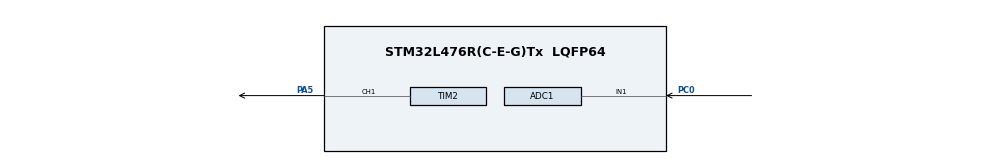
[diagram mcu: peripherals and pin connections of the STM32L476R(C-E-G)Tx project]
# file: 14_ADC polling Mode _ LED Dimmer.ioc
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ADC1.Channel-0\#ChannelRegularConversion=ADC_CHANNEL_1
ADC1.EnableAnalogWatchDog1=false
ADC1.NbrOfConversionFlag=1
ADC1.OffsetNumber-0\#ChannelRegularConversion=ADC_OFFSET_NONE
ADC1.Rank-0\#ChannelRegularConversion=1
ADC1.SamplingTime-0\#ChannelRegularConversion=ADC_SAMPLETIME_2CYCLES_5
ADC1.master=1
Mcu.Family=STM32L4
Mcu.Name=STM32L476R(C-E-G)Tx
Mcu.Package=LQFP64
NVIC.PriorityGroup=NVIC_PRIORITYGROUP_4
PA5.Signal=S_TIM2_CH1
PC0.Signal=ADCx_IN1
ProjectManager.HeapSize=0x200
ProjectManager.StackSize=0x400
ProjectManager.TargetToolchain=STM32CubeIDE
RCC.ADCFreq_Value=12000000
RCC.HSE_VALUE=8000000
RCC.HSI_VALUE=16000000
RCC.LSE_VALUE=32768
RCC.MSI_VALUE=4000000
RCC.PLLSAI1N=18
RCC.PLLSAI1R=RCC_PLLR_DIV6
RCC.USBFreq_Value=36000000
RCC.VCOOutputFreq_Value=32000000
SH.ADCx_IN1.0=ADC1_IN1,IN1-Single-Ended
SH.S_TIM2_CH1.0=TIM2_CH1,PWM Generation1 CH1
TIM2.Channel-PWM\ Generation1\ CH1=TIM_CHANNEL_1
TIM2.Period=1000
TIM2.Prescaler=3
TIM2.Pulse-PWM\ Generation1\ CH1=500
VP_TIM2_VS_ClockSourceINT.Mode=Internal
board=custom

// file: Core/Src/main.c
/* USER CODE BEGIN Header */
/**
  ******************************************************************************
  * @file           : main.c
  * @brief          : Main program body
  ******************************************************************************
  * @attention
  *
  * Copyright (c) 2023 STMicroelectronics.
  * All rights reserved.
  *
  * This software is licensed under terms that can be found in the LICENSE file
  * in the root directory of this software component.
  * If no LICENSE file comes with this software, it is provided AS-IS.
  *
  ******************************************************************************
  */
/* USER CODE END Header */
#include "main.h"

ADC_HandleTypeDef hadc1;

TIM_HandleTypeDef htim2;

void SystemClock_Config(void);
static void MX_GPIO_Init(void);
static void MX_ADC1_Init(void);
static void MX_TIM2_Init(void);

/* USER CODE BEGIN 0 */
uint16_t ADC_RES = 0;
uint32_t k = 0;

/* USER CODE END 0 */

int main(void)
{

  /* MCU Configuration--------------------------------------------------------*/

  /* Reset of all peripherals, Initializes the Flash interface and the Systick. */
  HAL_Init();

  /* Configure the system clock */
  SystemClock_Config();

  /* Initialize all configured peripherals */
  MX_GPIO_Init();
  MX_ADC1_Init();
  MX_TIM2_Init();
  /* USER CODE BEGIN 2 */
  HAL_TIM_PWM_Start(&htim2,TIM_CHANNEL_1);
  // Calibrate The ADC On Power-Up For Better Accuracy
  HAL_ADCEx_Calibration_Start(&hadc1,ADC_SINGLE_ENDED);

  /* USER CODE END 2 */

  /* Infinite loop */
  while (1)
  {

    /* USER CODE BEGIN 3 */
    // Start ADC Conversion
    HAL_ADC_Start(&hadc1);
    // Poll ADC1 Perihperal & TimeOut = 1mSec
    HAL_ADC_PollForConversion(&hadc1, 5);
    // Read The ADC Conversion Result & Map It To PWM DutyCycle
    ADC_RES = HAL_ADC_GetValue(&hadc1);
    TIM2->CCR1 = (ADC_RES<<10);
    k=(ADC_RES<<10);
    HAL_Delay(5);
  }
  /* USER CODE END 3 */
}

void SystemClock_Config(void)
{
  RCC_OscInitTypeDef RCC_OscInitStruct = {0};
  RCC_ClkInitTypeDef RCC_ClkInitStruct = {0};

  /** Configure the main internal regulator output voltage
  */
  if (HAL_PWREx_ControlVoltageScaling(PWR_REGULATOR_VOLTAGE_SCALE1) != HAL_OK)
  {
    Error_Handler();
  }

  /** Initializes the RCC Oscillators according to the specified parameters
  * in the RCC_OscInitTypeDef structure.
  */
  RCC_OscInitStruct.OscillatorType = RCC_OSCILLATORTYPE_MSI;
  RCC_OscInitStruct.MSIState = RCC_MSI_ON;
  RCC_OscInitStruct.MSICalibrationValue = 0;
  RCC_OscInitStruct.MSIClockRange = RCC_MSIRANGE_6;
  RCC_OscInitStruct.PLL.PLLState = RCC_PLL_NONE;
  if (HAL_RCC_OscConfig(&RCC_OscInitStruct) != HAL_OK)
  {
    Error_Handler();
  }

  /** Initializes the CPU, AHB and APB buses clocks
  */
  RCC_ClkInitStruct.ClockType = RCC_CLOCKTYPE_HCLK|RCC_CLOCKTYPE_SYSCLK
                              |RCC_CLOCKTYPE_PCLK1|RCC_CLOCKTYPE_PCLK2;
  RCC_ClkInitStruct.SYSCLKSource = RCC_SYSCLKSOURCE_MSI;
  RCC_ClkInitStruct.AHBCLKDivider = RCC_SYSCLK_DIV1;
  RCC_ClkInitStruct.APB1CLKDivider = RCC_HCLK_DIV1;
  RCC_ClkInitStruct.APB2CLKDivider = RCC_HCLK_DIV1;

  if (HAL_RCC_ClockConfig(&RCC_ClkInitStruct, FLASH_LATENCY_0) != HAL_OK)
  {
    Error_Handler();
  }
}

static void MX_ADC1_Init(void)
{

  ADC_MultiModeTypeDef multimode = {0};
  ADC_ChannelConfTypeDef sConfig = {0};

  /** Common config
  */
  hadc1.Instance = ADC1;
  hadc1.Init.ClockPrescaler = ADC_CLOCK_ASYNC_DIV1;
  hadc1.Init.Resolution = ADC_RESOLUTION_12B;
  hadc1.Init.DataAlign = ADC_DATAALIGN_RIGHT;
  hadc1.Init.ScanConvMode = ADC_SCAN_DISABLE;
  hadc1.Init.EOCSelection = ADC_EOC_SINGLE_CONV;
  hadc1.Init.LowPowerAutoWait = DISABLE;
  hadc1.Init.ContinuousConvMode = DISABLE;
  hadc1.Init.NbrOfConversion = 1;
  hadc1.Init.DiscontinuousConvMode = DISABLE;
  hadc1.Init.ExternalTrigConv = ADC_SOFTWARE_START;
  hadc1.Init.ExternalTrigConvEdge = ADC_EXTERNALTRIGCONVEDGE_NONE;
  hadc1.Init.DMAContinuousRequests = DISABLE;
  hadc1.Init.Overrun = ADC_OVR_DATA_PRESERVED;
  hadc1.Init.OversamplingMode = DISABLE;
  if (HAL_ADC_Init(&hadc1) != HAL_OK)
  {
    Error_Handler();
  }

  /** Configure the ADC multi-mode
  */
  multimode.Mode = ADC_MODE_INDEPENDENT;
  if (HAL_ADCEx_MultiModeConfigChannel(&hadc1, &multimode) != HAL_OK)
  {
    Error_Handler();
  }

  /** Configure Regular Channel
  */
  sConfig.Channel = ADC_CHANNEL_1;
  sConfig.Rank = ADC_REGULAR_RANK_1;
  sConfig.SamplingTime = ADC_SAMPLETIME_2CYCLES_5;
  sConfig.SingleDiff = ADC_SINGLE_ENDED;
  sConfig.OffsetNumber = ADC_OFFSET_NONE;
  sConfig.Offset = 0;
  if (HAL_ADC_ConfigChannel(&hadc1, &sConfig) != HAL_OK)
  {
    Error_Handler();
  }

}

static void MX_TIM2_Init(void)
{

  TIM_ClockConfigTypeDef sClockSourceConfig = {0};
  TIM_MasterConfigTypeDef sMasterConfig = {0};
  TIM_OC_InitTypeDef sConfigOC = {0};

  htim2.Instance = TIM2;
  htim2.Init.Prescaler = 3;
  htim2.Init.CounterMode = TIM_COUNTERMODE_UP;
  htim2.Init.Period = 1000;
  htim2.Init.ClockDivision = TIM_CLOCKDIVISION_DIV1;
  htim2.Init.AutoReloadPreload = TIM_AUTORELOAD_PRELOAD_DISABLE;
  if (HAL_TIM_Base_Init(&htim2) != HAL_OK)
  {
    Error_Handler();
  }
  sClockSourceConfig.ClockSource = TIM_CLOCKSOURCE_INTERNAL;
  if (HAL_TIM_ConfigClockSource(&htim2, &sClockSourceConfig) != HAL_OK)
  {
    Error_Handler();
  }
  if (HAL_TIM_PWM_Init(&htim2) != HAL_OK)
  {
    Error_Handler();
  }
  sMasterConfig.MasterOutputTrigger = TIM_TRGO_RESET;
  sMasterConfig.MasterSlaveMode = TIM_MASTERSLAVEMODE_DISABLE;
  if (HAL_TIMEx_MasterConfigSynchronization(&htim2, &sMasterConfig) != HAL_OK)
  {
    Error_Handler();
  }
  sConfigOC.OCMode = TIM_OCMODE_PWM1;
  sConfigOC.Pulse = 500;
  sConfigOC.OCPolarity = TIM_OCPOLARITY_HIGH;
  sConfigOC.OCFastMode = TIM_OCFAST_DISABLE;
  if (HAL_TIM_PWM_ConfigChannel(&htim2, &sConfigOC, TIM_CHANNEL_1) != HAL_OK)
  {
    Error_Handler();
  }
  HAL_TIM_MspPostInit(&htim2);

}

static void MX_GPIO_Init(void)
{

  /* GPIO Ports Clock Enable */
  __HAL_RCC_GPIOC_CLK_ENABLE();
  __HAL_RCC_GPIOA_CLK_ENABLE();

}

void Error_Handler(void)
{
  __disable_irq();
  while (1)
  {
  }
}
